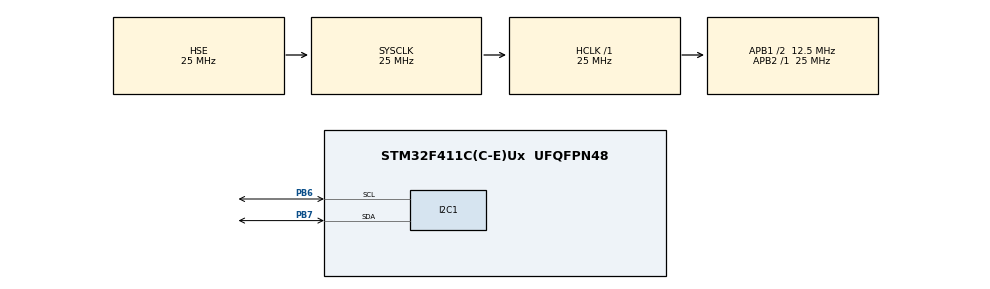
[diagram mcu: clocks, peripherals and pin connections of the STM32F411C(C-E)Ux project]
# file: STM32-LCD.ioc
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Mcu.Family=STM32F4
Mcu.Name=STM32F411C(C-E)Ux
Mcu.Package=UFQFPN48
NVIC.PriorityGroup=NVIC_PRIORITYGROUP_4
PA13.Mode=Serial_Wire
PA13.Signal=SYS_JTMS-SWDIO
PA14.Mode=Serial_Wire
PA14.Signal=SYS_JTCK-SWCLK
PB6.GPIO_Pu=GPIO_PULLUP
PB6.Mode=I2C
PB6.Signal=I2C1_SCL
PB7.GPIO_Pu=GPIO_PULLUP
PB7.Mode=I2C
PB7.Signal=I2C1_SDA
PH0\ -\ OSC_IN.Mode=HSE-External-Oscillator
PH0\ -\ OSC_IN.Signal=RCC_OSC_IN
PH1\ -\ OSC_OUT.Mode=HSE-External-Oscillator
PH1\ -\ OSC_OUT.Signal=RCC_OSC_OUT
ProjectManager.HeapSize=0x200
ProjectManager.StackSize=0x400
ProjectManager.TargetToolchain=STM32CubeIDE
RCC.48MHZClocksFreq_Value=37500000
RCC.AHBFreq_Value=25000000
RCC.APB1CLKDivider=RCC_HCLK_DIV2
RCC.APB1Freq_Value=12500000
RCC.APB1TimFreq_Value=25000000
RCC.APB2Freq_Value=25000000
RCC.APB2TimFreq_Value=25000000
RCC.CortexFreq_Value=25000000
RCC.HCLKFreq_Value=25000000
RCC.HSE_VALUE=25000000
RCC.HSI_VALUE=16000000
RCC.LSE_VALUE=32768
RCC.PLLM=12
RCC.PLLN=72
RCC.PLLSourceVirtual=RCC_PLLSOURCE_HSE
RCC.SYSCLKFreq_VALUE=25000000
RCC.SYSCLKSource=RCC_SYSCLKSOURCE_HSE
RCC.VCOOutputFreq_Value=150000000
TIM2.Prescaler=25-1
VP_TIM2_VS_ClockSourceINT.Mode=Internal
board=custom

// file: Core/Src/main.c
/* @file  main.c
   @brief main application for STM32 and 16x2 LCD Display
   @author Avinashee Tech
*/

/* USER CODE END Header */
#include "main.h"

/* USER CODE BEGIN Includes */
#include "stm32f4xx_hal.h"
#include "lcd_i2c.h"

/* USER CODE END Includes */

/* USER CODE BEGIN PM */
#define LCD_COLS       16    // LCD Display has 16 columns
#define LCD_ROWS       2     // LCD Display has 2 rows
/* USER CODE END PM */

I2C_HandleTypeDef hi2c1;

TIM_HandleTypeDef htim2;

void SystemClock_Config(void);
static void MX_GPIO_Init(void);
static void MX_I2C1_Init(void);
static void MX_TIM2_Init(void);

/* USER CODE BEGIN 0 */
/**
* @brief LCD Display Start Message
* @retval None
* @param None
*/
void lcd_home_message(void){
    /*lcd custom characters*/
    uint8_t subscribe[] = {0x00,0x08,0x0C,0x0E,0x0C,0x08,0x00,0x1F};
    uint8_t share_back[] = {0x08,0x0C,0x1E,0x1F,0x1E,0x0C,0x08,0x00};
    uint8_t share_front[] = {0x00,0x00,0x03,0x07,0x0F,0x1C,0x18,0x10};
    uint8_t like[] = {0x00,0x0A,0x1F,0x1F,0x1F,0x0E,0x04,0x00};

    /*
      0  1  2  3  4  5  6  7  8  9  10 11 12 13 14 15
    0 N  a  m  a  s  t  e     &
    1 W  e  l  c  o  m  e     t  o
    */
    clear();
    setCursor(0,0);
    send_string("Namaste &");
    setCursor(0,1);
    send_string("Welcome to");

    HAL_Delay(4000);  //wait 4s

    /*
      0  1  2  3  4  5  6  7  8  9  10 11 12 13 14 15
    0 A  v  i  n  a  s  h  e  e     T  e  c  h
    1      ➦      ▶ s  u  b  s  c  r  i  b  e
    */
     clear();
     setCursor(0,0);
     send_string("Avinashee");
     setCursor(10,0);
     send_string("Tech");

     createChar(0,subscribe);
     createChar(1,share_back);
     createChar(2,share_front);
     createChar(3,like);
     //subscribe
     setCursor(5,1);
     lcd_write(0);
     setCursor(6,1);
     send_string("subscribe");
     //share
     setCursor(2,1);
     lcd_write(2);
     setCursor(3,1);
     lcd_write(1);
     //like
     setCursor(0,1);
     lcd_write(3);

  }
/* USER CODE END 0 */

int main(void)
{

  /* MCU Configuration--------------------------------------------------------*/

  /* Reset of all peripherals, Initializes the Flash interface and the Systick. */
  HAL_Init();

  /* Configure the system clock */
  SystemClock_Config();

  /* Initialize all configured peripherals */
  MX_GPIO_Init();
  MX_I2C1_Init();
  MX_TIM2_Init();
  /* USER CODE BEGIN 2 */

  HAL_TIM_Base_Start(&htim2);  //for delay in microseconds

  lcd_init(LCD_COLS,LCD_ROWS);
  backlight();
  lcd_home_message();

  /* USER CODE END 2 */

  /* Infinite loop */
  while (1)
  {

  }
}

void SystemClock_Config(void)
{
  RCC_OscInitTypeDef RCC_OscInitStruct = {0};
  RCC_ClkInitTypeDef RCC_ClkInitStruct = {0};

  /** Configure the main internal regulator output voltage
  */
  __HAL_RCC_PWR_CLK_ENABLE();
  __HAL_PWR_VOLTAGESCALING_CONFIG(PWR_REGULATOR_VOLTAGE_SCALE1);

  /** Initializes the RCC Oscillators according to the specified parameters
  * in the RCC_OscInitTypeDef structure.
  */
  RCC_OscInitStruct.OscillatorType = RCC_OSCILLATORTYPE_HSE;
  RCC_OscInitStruct.HSEState = RCC_HSE_ON;
  RCC_OscInitStruct.PLL.PLLState = RCC_PLL_NONE;
  if (HAL_RCC_OscConfig(&RCC_OscInitStruct) != HAL_OK)
  {
    Error_Handler();
  }

  /** Initializes the CPU, AHB and APB buses clocks
  */
  RCC_ClkInitStruct.ClockType = RCC_CLOCKTYPE_HCLK|RCC_CLOCKTYPE_SYSCLK
                              |RCC_CLOCKTYPE_PCLK1|RCC_CLOCKTYPE_PCLK2;
  RCC_ClkInitStruct.SYSCLKSource = RCC_SYSCLKSOURCE_HSE;
  RCC_ClkInitStruct.AHBCLKDivider = RCC_SYSCLK_DIV1;
  RCC_ClkInitStruct.APB1CLKDivider = RCC_HCLK_DIV2;
  RCC_ClkInitStruct.APB2CLKDivider = RCC_HCLK_DIV1;

  if (HAL_RCC_ClockConfig(&RCC_ClkInitStruct, FLASH_LATENCY_0) != HAL_OK)
  {
    Error_Handler();
  }
}

static void MX_I2C1_Init(void)
{

  hi2c1.Instance = I2C1;
  hi2c1.Init.ClockSpeed = 100000;
  hi2c1.Init.DutyCycle = I2C_DUTYCYCLE_2;
  hi2c1.Init.OwnAddress1 = 0;
  hi2c1.Init.AddressingMode = I2C_ADDRESSINGMODE_7BIT;
  hi2c1.Init.DualAddressMode = I2C_DUALADDRESS_DISABLE;
  hi2c1.Init.OwnAddress2 = 0;
  hi2c1.Init.GeneralCallMode = I2C_GENERALCALL_DISABLE;
  hi2c1.Init.NoStretchMode = I2C_NOSTRETCH_DISABLE;
  if (HAL_I2C_Init(&hi2c1) != HAL_OK)
  {
    Error_Handler();
  }

}

static void MX_TIM2_Init(void)
{

  TIM_ClockConfigTypeDef sClockSourceConfig = {0};
  TIM_MasterConfigTypeDef sMasterConfig = {0};

  htim2.Instance = TIM2;
  htim2.Init.Prescaler = 25-1;
  htim2.Init.CounterMode = TIM_COUNTERMODE_UP;
  htim2.Init.Period = 4294967295;
  htim2.Init.ClockDivision = TIM_CLOCKDIVISION_DIV1;
  htim2.Init.AutoReloadPreload = TIM_AUTORELOAD_PRELOAD_DISABLE;
  if (HAL_TIM_Base_Init(&htim2) != HAL_OK)
  {
    Error_Handler();
  }
  sClockSourceConfig.ClockSource = TIM_CLOCKSOURCE_INTERNAL;
  if (HAL_TIM_ConfigClockSource(&htim2, &sClockSourceConfig) != HAL_OK)
  {
    Error_Handler();
  }
  sMasterConfig.MasterOutputTrigger = TIM_TRGO_RESET;
  sMasterConfig.MasterSlaveMode = TIM_MASTERSLAVEMODE_DISABLE;
  if (HAL_TIMEx_MasterConfigSynchronization(&htim2, &sMasterConfig) != HAL_OK)
  {
    Error_Handler();
  }

}

static void MX_GPIO_Init(void)
{

  /* GPIO Ports Clock Enable */
  __HAL_RCC_GPIOH_CLK_ENABLE();
  __HAL_RCC_GPIOA_CLK_ENABLE();
  __HAL_RCC_GPIOB_CLK_ENABLE();

}

void Error_Handler(void)
{
  __disable_irq();
  while (1)
  {
  }
}
